# f29h85x_cpu_sys_regs register map
Vendor: Texas Instruments
Peripheral module from a debugger description file (folder C29).
Registers are 32-bit, read-write, no defined reset value unless marked. A register's access mark holds for its fields unless they carry their own. Offsets are as the file gives them; lines under a group give offsets from that group; [hi:lo] are bit positions; {n}, {i} and the like mark numbered series; 'fields as' and 'values as' point back to an identical list; <NAME> marks a mode.

## CPU_SYS_REGS — CPU SYS Registers
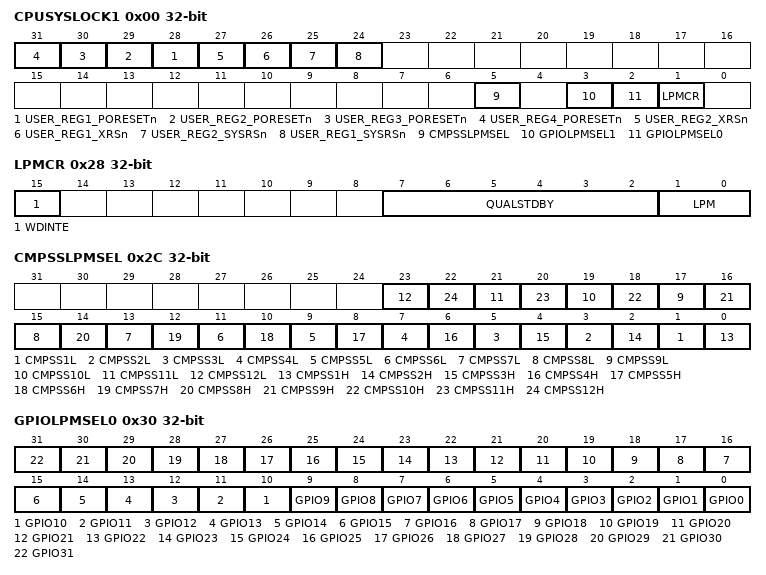
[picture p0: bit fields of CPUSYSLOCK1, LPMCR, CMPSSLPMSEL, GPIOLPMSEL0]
0x00 CPUSYSLOCK1 — Lock bit for CPUSYS registers
  [n+27] USER_REG{n}_PORESETn (n=1..4) — Lock bit for USER_REG{n}_PORESETn
  [27] USER_REG2_XRSn — Lock bit for USER_REG2_XRSn
  [26] USER_REG1_XRSn — Lock bit for USER_REG1_XRSn
  [25] USER_REG2_SYSRSn — Lock bit for USER_REG2_SYSRSn
  [24] USER_REG1_SYSRSn — Lock bit for USER_REG1_SYSRSn
  [5] CMPSSLPMSEL — Lock bit for CMPSSLPMSEL register
  [3] GPIOLPMSEL1 — Lock bit for GPIOLPMSEL1 Register
  [2] GPIOLPMSEL0 — Lock bit for GPIOLPMSEL0 Register
  [1] LPMCR — Lock bit for LPMCR Register
0x0C CPUID ro — Indicates CPU1, CPU2.. CPU6
  [1:0] CPUID — Indicates CPU1, CPU2, CPU3, CPU4, CPU5 or CPU6
0x28 LPMCR — LPM Control Register
  [15] WDINTE — Enable for WDINT wakeup from STANDBY
  [7:2] QUALSTDBY — STANDBY Wakeup Pin Qualification Setting
  [1:0] LPM — Low Power Mode setting
0x2C CMPSSLPMSEL — CMPSS LPM Wakeup select registers
  [2n-1] CMPSS{n}L (n=1..12) — CMPSS{n}L Enable for LPM Wakeup
  [2n-2] CMPSS{n}H (n=1..12) — CMPSS{n}H Enable for LPM Wakeup
0x30 GPIOLPMSEL0 — GPIO LPM Wakeup select registers
  [n] GPIO{n} (n=0..31) — GPIO{n} Enable for LPM Wakeup
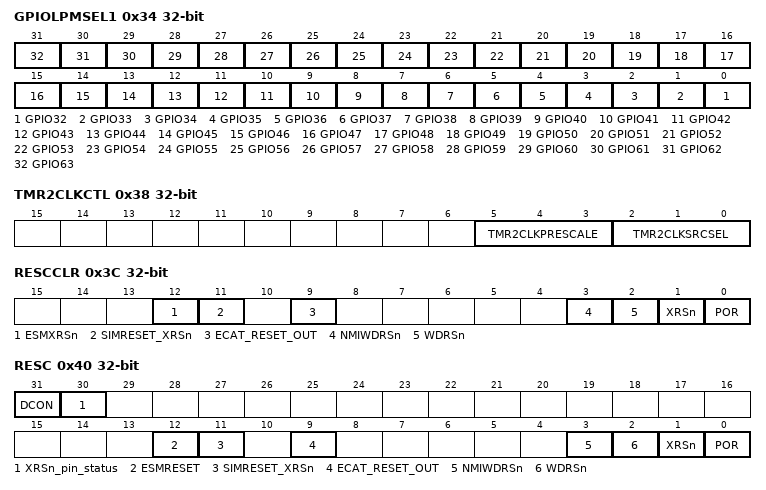
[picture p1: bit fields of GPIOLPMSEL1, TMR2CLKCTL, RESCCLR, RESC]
0x34 GPIOLPMSEL1 — GPIO LPM Wakeup select registers
  [n-32] GPIO{n} (n=32..63) — GPIO{n} Enable for LPM Wakeup
0x38 TMR2CLKCTL — Timer2 Clock Measurement functionality control register
  [5:3] TMR2CLKPRESCALE — CPU Timer 2 Clock Pre-Scale Value
  [2:0] TMR2CLKSRCSEL — CPU Timer 2 Clock Source Select Bit
0x3C RESCCLR — Reset Cause Clear Register
  [12] ESMXRSn — ESMXRSn Reset Cause Clear Bit
  [11] SIMRESET_XRSn — SIMRESET_XRSn POR Reset Cause Clear Bit
  [9] ECAT_RESET_OUT — ECAT_RESET_OUT POR Reset Cause Clear Bit
  [3] NMIWDRSn — NMIWDRSn POR Reset Cause Clear Bit
  [2] WDRSn — WDRSn POR Reset Cause Clear Bit
  [1] XRSn — XRSn POR Reset Cause Clear Bit
  [0] POR — POR POR Reset Cause Clear Bit
0x40 RESC ro — Reset Cause register
  [31] DCON — Debugger connection status to C29x CPU
  [30] XRSn_pin_status
  [12] ESMRESET — ESMRESET Reset Cause Indication Bit
  [11] SIMRESET_XRSn — SIMRESET_XRSn Reset Cause Indication Bit
  [9] ECAT_RESET_OUT — ECAT_RESET_OUT Reset Cause Indication Bit
  [3] NMIWDRSn — NMIWDRSn Reset Cause Indication Bit
  [2] WDRSn — WDRSn Reset Cause Indication Bit
  [1] XRSn — XRSn Reset Cause Indication Bit
  [0] POR — POR Reset Cause Indication Bit
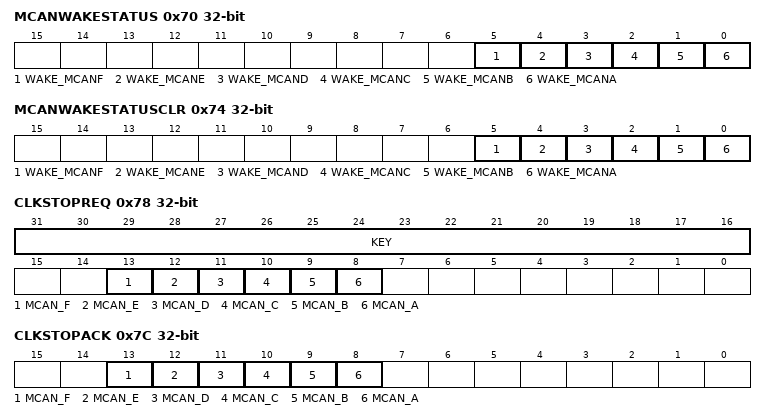
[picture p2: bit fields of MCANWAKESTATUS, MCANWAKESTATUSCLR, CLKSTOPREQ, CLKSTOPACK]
0x70 MCANWAKESTATUS ro
  [5] WAKE_MCANF — WAKE_MCANF Wake Status
  [4] WAKE_MCANE — WAKE_MCANE Wake Status
  [3] WAKE_MCAND — WAKE_MCAND Wake Status
  [2] WAKE_MCANC — WAKE_MCANC Wake Status
  [1] WAKE_MCANB — WAKE_MCANB Wake Status
  [0] WAKE_MCANA — WAKE_MCANA Wake Status
0x74 MCANWAKESTATUSCLR — MCAN Wake Status Clear Register
  [5] WAKE_MCANF — Cear bit for MCANWAKESTATUS.WAKE_MCANF bit
  [4] WAKE_MCANE — Cear bit for MCANWAKESTATUS.WAKE_MCANE bit
  [3] WAKE_MCAND — Cear bit for MCANWAKESTATUS.WAKE_MCAND bit
  [2] WAKE_MCANC — Cear bit for MCANWAKESTATUS.WAKE_MCANC bit
  [1] WAKE_MCANB — Cear bit for MCANWAKESTATUS.WAKE_MCANB bit
  [0] WAKE_MCANA — Cear bit for MCANWAKESTATUS.WAKE_MCANA bit
0x78 CLKSTOPREQ — Peripheral Clock Stop Request Register
  [31:16] KEY — Key for register write
  [13] MCAN_F — MCAN_F Clock Stop Request Bit
  [12] MCAN_E — MCAN_E Clock Stop Request Bit
  [11] MCAN_D — MCAN_D Clock Stop Request Bit
  [10] MCAN_C — MCAN_C Clock Stop Request Bit
  [9] MCAN_B — MCAN_B Clock Stop Request Bit
  [8] MCAN_A — MCAN_A Clock Stop Request Bit
0x7C CLKSTOPACK ro — Peripheral Clock Stop Ackonwledge Register
  [13] MCAN_F — MCAN_F Clock Stop Ack Bit
  [12] MCAN_E — MCAN_E Clock Stop Ack Bit
  [11] MCAN_D — MCAN_D Clock Stop Ack Bit
  [10] MCAN_C — MCAN_C Clock Stop Ack Bit
  [9] MCAN_B — MCAN_B Clock Stop Ack Bit
  [8] MCAN_A — MCAN_A Clock Stop Ack Bit
0x80 USER_REG1_SYSRSn — Software Configurable registers reset by SYSRSn
  [31:0] BITS — SW configurable bits
0x84 USER_REG2_SYSRSn — Software Configurable registers reset by SYSRSn
  [31:0] BITS — SW configurable bits
0x88 USER_REG1_XRSn — Software Configurable registers reset by XRSn
  [31:0] BITS — SW configurable bits
0x8C USER_REG2_XRSn — Software Configurable registers reset by XRSn
  [31:0] BITS — SW configurable bits
{0x8C+4i} USER_REG{i}_PORESETn (i=1..4) — Software Configurable registers reset by PORESETn
  [31:0] BITS — SW configurable bits
0xA0 JTAG_MMR_REG access not given — Readback of JTAG registers for test purpose
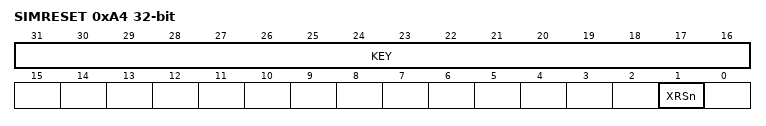
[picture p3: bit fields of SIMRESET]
0xA4 SIMRESET — Simulated Reset Register
  [31:16] KEY — Key value to enable write
  [1] XRSn — Generates a simulated XRSn
0xA8 PARITY_TEST_ALT2 — Enables parity test
  [3:0] TESTEN — Parity test enable configuration
